# ESP32-H4 register map
Vendor: ESPRESSIF SYSTEMS (SHANGHAI) CO., LTD.; Series: ESP32 H-Series; File version: 1
CPU: RV32IMAC r0p0, little endian, no MPU, no FPU, 0 interrupt priority bits
Address unit: 32 bits
Registers are 32-bit, read-write, reset 0x0 unless marked. A register's access mark holds for its fields unless they carry their own. Offsets are from the block's base; [hi:lo] are bit positions; {n}, {i} and the like mark numbered series.

## GPIO_SD — Sigma-Delta Modulation
Base 0x60093E00
0x00 CLOCK_GATE — Clock Gating Configure Register
  [0] CLK_EN — Clock enable bit of configuration registers for sigma delta modulation.
0x04 SIGMADELTA_MISC — MISC Register
  [0] FUNCTION_CLK_EN — Configures whether or not to enable the clock for sigma delta modulation.\\ 0: Not enable\\ 1: Enable\\%\label{fielddesc:GPIOSDSPISWAP}- [GPIOSD_SPI_SWAP] Reserved.
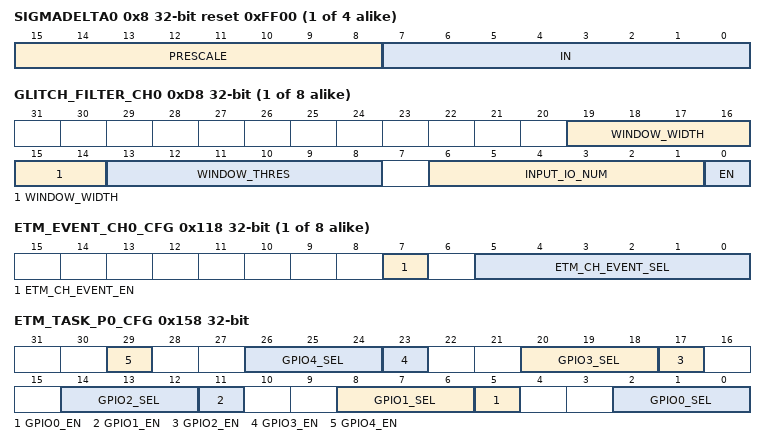
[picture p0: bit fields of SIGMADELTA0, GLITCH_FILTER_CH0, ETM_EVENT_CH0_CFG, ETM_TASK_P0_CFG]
{0x8+4i} SIGMADELTA{i} (i=0..3) reset 0xFF00 — Duty cycle configuration register for SDM channel {i}
  [15:8] PRESCALE — Configures the divider value to divide IO MUX operating clock. \\
  [7:0] IN — Configures the duty cycle of sigma delta modulation output. \\
{0xD8+4i} GLITCH_FILTER_CH{i} (i=0..7) — Glitch Filter Configure Register of Channel{i}
  [19:14] WINDOW_WIDTH — Configures the window width for Glitch Filter. The effective value of window width is 0 ~ 63. \\ Measurement unit: IO MUX operating clock cycle\\
  [13:8] WINDOW_THRES — Configures the window threshold for Glitch Filter. The window threshold should be less than or equal to GPIOSD_FILTER_CH%s_WINDOW_WIDTH.\\ %see DOC-4768\\ Measurement unit: IO MUX operating clock cycle\\
  [6:1] INPUT_IO_NUM — Configures to select the input GPIO for Glitch Filter. \\ 0: Select GPIO0\\ 1: Select GPIO1\\ ......\\ 38: Select GPIO38\\ 39: Select GPIO39\\ 40 ~ 63: Reserved\\
  [0] EN — Configures whether or not to enable channel %s of Glitch Filter.\\ 0: Not enable\\ 1: Enable\\
{0x118+4i} ETM_EVENT_CH{i}_CFG (i=0..7) — ETM configuration register for channel {i}
  [7] ETM_CH_EVENT_EN — Configures whether or not to enable ETM event send.\\ 0: Not enable\\ 1: Enable\\
  [5:0] ETM_CH_EVENT_SEL — Configures to select GPIO for ETM event channel.\\ 0: Select GPIO0\\ 1: Select GPIO1\\ ......\\ 38: Select GPIO38\\ 39: Select GPIO39\\ 40 ~ 63: Reserved\\
0x158 ETM_TASK_P0_CFG — GPIO selection register 0 for ETM
  [6n+5] GPIO{n}_EN (n=0..4) — Enable GPIO{n} for ETM task
  [6n+2:6n] GPIO{n}_SEL (n=0..4) — Select GPIO{n} for ETM task
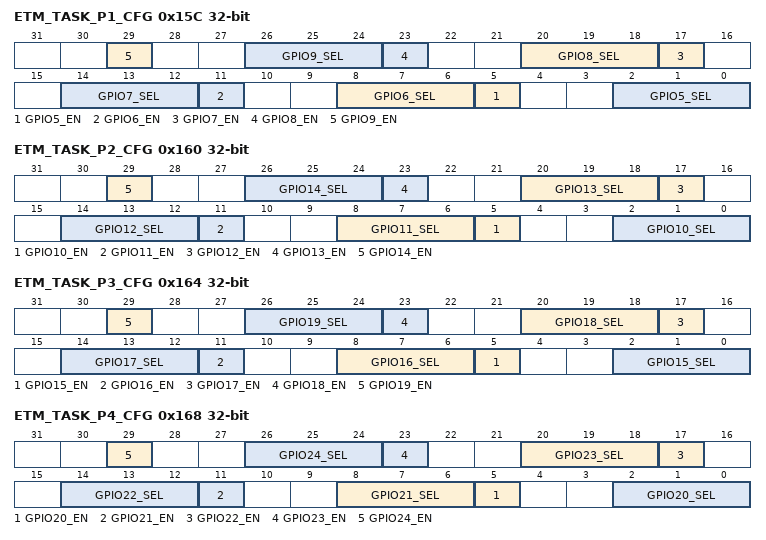
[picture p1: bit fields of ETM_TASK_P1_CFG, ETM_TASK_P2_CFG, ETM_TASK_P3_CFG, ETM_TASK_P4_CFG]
0x15C ETM_TASK_P1_CFG — GPIO selection register 1 for ETM
  [6n-25] GPIO{n}_EN (n=5..9) — Enable GPIO{n} for ETM task
  [6n-28:6n-30] GPIO{n}_SEL (n=5..9) — Select GPIO{n} for ETM task
0x160 ETM_TASK_P2_CFG — GPIO selection register 2 for ETM
  [6n-55] GPIO{n}_EN (n=10..14) — Enable GPIO{n} for ETM task
  [6n-58:6n-60] GPIO{n}_SEL (n=10..14) — Select GPIO{n} for ETM task
0x164 ETM_TASK_P3_CFG — GPIO selection register 3 for ETM
  [6n-85] GPIO{n}_EN (n=15..19) — Enable GPIO{n} for ETM task
  [6n-88:6n-90] GPIO{n}_SEL (n=15..19) — Select GPIO{n} for ETM task
0x168 ETM_TASK_P4_CFG — GPIO selection register 4 for ETM
  [6n-115] GPIO{n}_EN (n=20..24) — Enable GPIO{n} for ETM task
  [6n-118:6n-120] GPIO{n}_SEL (n=20..24) — Select GPIO{n} for ETM task
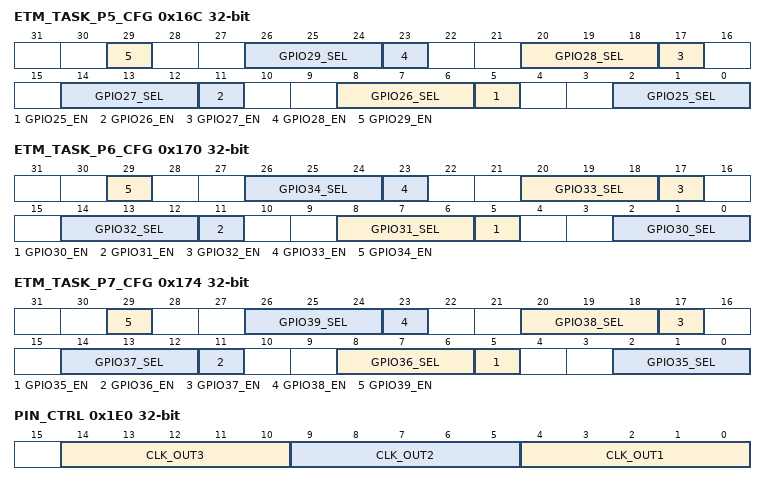
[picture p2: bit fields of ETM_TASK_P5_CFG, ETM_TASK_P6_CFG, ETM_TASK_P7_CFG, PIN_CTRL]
0x16C ETM_TASK_P5_CFG — GPIO selection register 5 for ETM
  [6n-145] GPIO{n}_EN (n=25..29) — Enable GPIO{n} for ETM task
  [6n-148:6n-150] GPIO{n}_SEL (n=25..29) — Select GPIO{n} for ETM task
0x170 ETM_TASK_P6_CFG — GPIO selection register 6 for ETM
  [6n-175] GPIO{n}_EN (n=30..34) — Enable GPIO{n} for ETM task
  [6n-178:6n-180] GPIO{n}_SEL (n=30..34) — Select GPIO{n} for ETM task
0x174 ETM_TASK_P7_CFG — GPIO selection register 7 for ETM
  [6n-205] GPIO{n}_EN (n=35..39) — Enable GPIO{n} for ETM task
  [6n-208:6n-210] GPIO{n}_SEL (n=35..39) — Select GPIO{n} for ETM task
0x1E0 PIN_CTRL — Clock Output Configuration Register
  [14:10] CLK_OUT3 — If you want to output clock for I2S to CLK_OUT_out3, set this register to 0x0. CLK_OUT_out3 can be found in peripheral output signals.
  [9:5] CLK_OUT2 — If you want to output clock for I2S to CLK_OUT_out2, set this register to 0x0. CLK_OUT_out2 can be found in peripheral output signals.
  [4:0] CLK_OUT1 — If you want to output clock for I2S to CLK_OUT_out1, set this register to 0x0. CLK_OUT_out1 can be found in peripheral output signals.
0x1FC VERSION — Version control register
